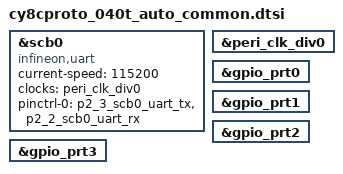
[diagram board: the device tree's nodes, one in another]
/*
 * SPDX-FileCopyrightText: <text>Copyright (c) 2026 Infineon Technologies AG,
 * or an affiliate of Infineon Technologies AG. All rights reserved.</text>
 *
 * SPDX-License-Identifier: Apache-2.0
 */

#include <zephyr/dt-bindings/input/input-event-codes.h>
#include "cy8cproto_040t_auto-pinctrl.dtsi"

uart0: &scb0 {
	compatible = "infineon,uart";
	status = "okay";
	current-speed = <115200>;
	clocks = <&peri_clk_div0>;
	pinctrl-0 = <&p2_3_scb0_uart_tx &p2_2_scb0_uart_rx>;
	pinctrl-names = "default";
};

&peri_clk_div0 {
	status = "okay";
};

&gpio_prt0 {
	status = "okay";
};

&gpio_prt1 {
	status = "okay";
};


&gpio_prt2 {
	status = "okay";
};

&gpio_prt3 {
	status = "okay";
};

